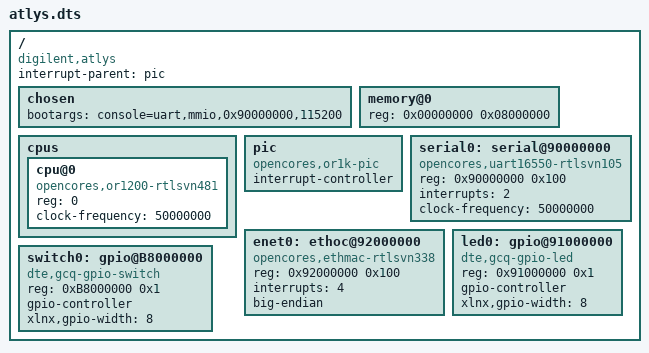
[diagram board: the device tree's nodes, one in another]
/dts-v1/;
/ {
  compatible = "digilent,atlys";
  #address-cells = <1>;
  #size-cells = <1>;
  interrupt-parent = <&pic>;

  chosen {
    bootargs = "console=uart,mmio,0x90000000,115200";
  };

  memory@0 {
    device_type = "memory";
    reg = <0x00000000 0x08000000>;
  };

  cpus {
    #address-cells = <1>;
    #size-cells = <0>;
    cpu@0 {
      compatible = "opencores,or1200-rtlsvn481";
      reg = <0>;
      clock-frequency = <50000000>;
    };
  };

  /*
   * OR1K PIC is built into CPU and accessed via special purpose
   * registers.  It is not addressable and, hence, has no 'reg'
   * property.
   */
  pic: pic {
    compatible = "opencores,or1k-pic";
    #interrupt-cells = <1>;
    interrupt-controller;
  };

  serial0: serial@90000000 {
    compatible = "opencores,uart16550-rtlsvn105", "ns16550a";
    reg = <0x90000000 0x100>;
    interrupts = <2>;
    clock-frequency = <50000000>;
  };

  enet0: ethoc@92000000 {
		compatible = "opencores,ethmac-rtlsvn338";
		reg = <0x92000000 0x100>;
		interrupts = <4>;
		big-endian;
	};

  led0: gpio@91000000 {
		compatible = "dte,gcq-gpio-led";
		reg = <0x91000000 0x1>;
		#gpio-cells = <2>;
		gpio-controller;
		xlnx,gpio-width = <8>;
	};

  switch0: gpio@B8000000 {
		compatible = "dte,gcq-gpio-switch";
		reg = <0xB8000000 0x1>;
		#gpio-cells = <2>;
		gpio-controller;
		xlnx,gpio-width = <8>;
	};
};
